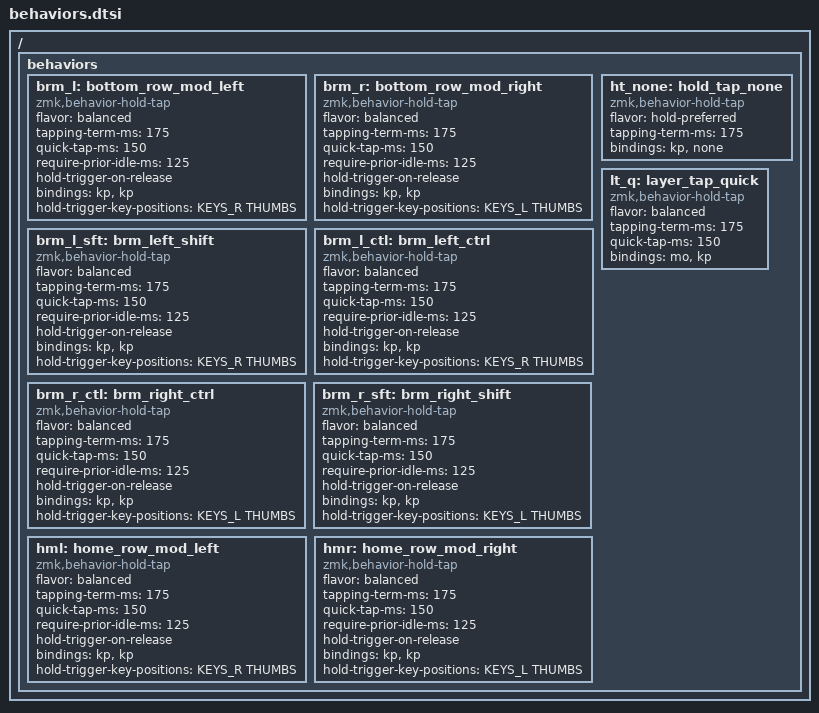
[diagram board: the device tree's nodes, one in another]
/*
 * Позиционные Bottom-Row Mods (BRM) с поддержкой Bilateral Combinations,
 * hold-trigger-on-release для одновременных аккордов модификаторов одной руки,
 * и кастомные поведения для 42 клавиш (3x6 + 3L/3R Thumbs)
 *
 * Схема индексов клавиш (0..41):
 * ╭────┬────┬────┬────┬────┬────╮   ╭────┬────┬────┬────┬────┬────╮
 * │ 00 │ 01 │ 02 │ 03 │ 04 │ 05 │   │ 06 │ 07 │ 08 │ 09 │ 10 │ 11 │
 * ├────┼────┼────┼────┼────┼────┤   ├────┼────┼────┼────┼────┼────┤
 * │ 12 │ 13 │ 14 │ 15 │ 16 │ 17 │   │ 18 │ 19 │ 20 │ 21 │ 22 │ 23 │
 * ├────┼────┼────┼────┼────┼────┤   ├────┼────┼────┼────┼────┼────┤
 * │ 24 │ 25 │ 26 │ 27 │ 28 │ 29 │   │ 30 │ 31 │ 32 │ 33 │ 34 │ 35 │
 * ╰────┴────┴────┼────┼────┼────┤   ├────┼────┼────┼────┴────┴────╯
 *                │ 36 │ 37 │ 38 │   │ 39 │ 40 │ 41 │
 *                ╰────┴────┴────╯   ╰────┴────┴────╯
 */

#define KEYS_L 0 1 2 3 4 5 12 13 14 15 16 17 24 25 26 27 28 29
#define KEYS_R 6 7 8 9 10 11 18 19 20 21 22 23 30 31 32 33 34 35
#define THUMBS 36 37 38 39 40 41

/ {
    behaviors {
        /*
         * Левые BRM (GUI, ALT, SHIFT, CTRL): Bilateral Combinations + hold-trigger-on-release
         * - Удержание >= 175 мс: гарантированный модификатор.
         * - Аккорд с противоположной рукой (KEYS_R) или тамбами: немедленная активация модификатора.
         * - hold-trigger-on-release: позволяет зажимать несколько модификаторов на одной руке
         *   (например, Ctrl + Shift слева для комбинаций с Esc/другой рукой).
         */
        brm_l: bottom_row_mod_left {
            compatible = "zmk,behavior-hold-tap";
            #binding-cells = <2>;
            flavor = "balanced";
            tapping-term-ms = <175>;
            quick-tap-ms = <150>;
            require-prior-idle-ms = <125>;
            hold-trigger-on-release;
            bindings = <&kp>, <&kp>;
            hold-trigger-key-positions = <KEYS_R THUMBS>;
        };

        /* Правые BRM (CTRL, SHIFT, ALT, GUI): Bilateral Combinations + hold-trigger-on-release */
        brm_r: bottom_row_mod_right {
            compatible = "zmk,behavior-hold-tap";
            #binding-cells = <2>;
            flavor = "balanced";
            tapping-term-ms = <175>;
            quick-tap-ms = <150>;
            require-prior-idle-ms = <125>;
            hold-trigger-on-release;
            bindings = <&kp>, <&kp>;
            hold-trigger-key-positions = <KEYS_L THUMBS>;
        };

        /* Псевдонимы для совместимости */
        brm_l_sft: brm_left_shift {
            compatible = "zmk,behavior-hold-tap";
            #binding-cells = <2>;
            flavor = "balanced";
            tapping-term-ms = <175>;
            quick-tap-ms = <150>;
            require-prior-idle-ms = <125>;
            hold-trigger-on-release;
            bindings = <&kp>, <&kp>;
            hold-trigger-key-positions = <KEYS_R THUMBS>;
        };

        brm_l_ctl: brm_left_ctrl {
            compatible = "zmk,behavior-hold-tap";
            #binding-cells = <2>;
            flavor = "balanced";
            tapping-term-ms = <175>;
            quick-tap-ms = <150>;
            require-prior-idle-ms = <125>;
            hold-trigger-on-release;
            bindings = <&kp>, <&kp>;
            hold-trigger-key-positions = <KEYS_R THUMBS>;
        };

        brm_r_ctl: brm_right_ctrl {
            compatible = "zmk,behavior-hold-tap";
            #binding-cells = <2>;
            flavor = "balanced";
            tapping-term-ms = <175>;
            quick-tap-ms = <150>;
            require-prior-idle-ms = <125>;
            hold-trigger-on-release;
            bindings = <&kp>, <&kp>;
            hold-trigger-key-positions = <KEYS_L THUMBS>;
        };

        brm_r_sft: brm_right_shift {
            compatible = "zmk,behavior-hold-tap";
            #binding-cells = <2>;
            flavor = "balanced";
            tapping-term-ms = <175>;
            quick-tap-ms = <150>;
            require-prior-idle-ms = <125>;
            hold-trigger-on-release;
            bindings = <&kp>, <&kp>;
            hold-trigger-key-positions = <KEYS_L THUMBS>;
        };

        /* Поведение для слоя Fn: удержание = модификатор, тап = ничего */
        ht_none: hold_tap_none {
            compatible = "zmk,behavior-hold-tap";
            #binding-cells = <2>;
            flavor = "hold-preferred";
            tapping-term-ms = <175>;
            bindings = <&kp>, <&none>;
        };

        /* Совместимость с именами hml, hmr для ZMK Studio */
        hml: home_row_mod_left {
            compatible = "zmk,behavior-hold-tap";
            #binding-cells = <2>;
            flavor = "balanced";
            tapping-term-ms = <175>;
            quick-tap-ms = <150>;
            require-prior-idle-ms = <125>;
            hold-trigger-on-release;
            bindings = <&kp>, <&kp>;
            hold-trigger-key-positions = <KEYS_R THUMBS>;
        };

        hmr: home_row_mod_right {
            compatible = "zmk,behavior-hold-tap";
            #binding-cells = <2>;
            flavor = "balanced";
            tapping-term-ms = <175>;
            quick-tap-ms = <150>;
            require-prior-idle-ms = <125>;
            hold-trigger-on-release;
            bindings = <&kp>, <&kp>;
            hold-trigger-key-positions = <KEYS_L THUMBS>;
        };

        /* Быстрый Layer-Tap */
        lt_q: layer_tap_quick {
            compatible = "zmk,behavior-hold-tap";
            #binding-cells = <2>;
            flavor = "balanced";
            tapping-term-ms = <175>;
            quick-tap-ms = <150>;
            bindings = <&mo>, <&kp>;
        };
    };
};
